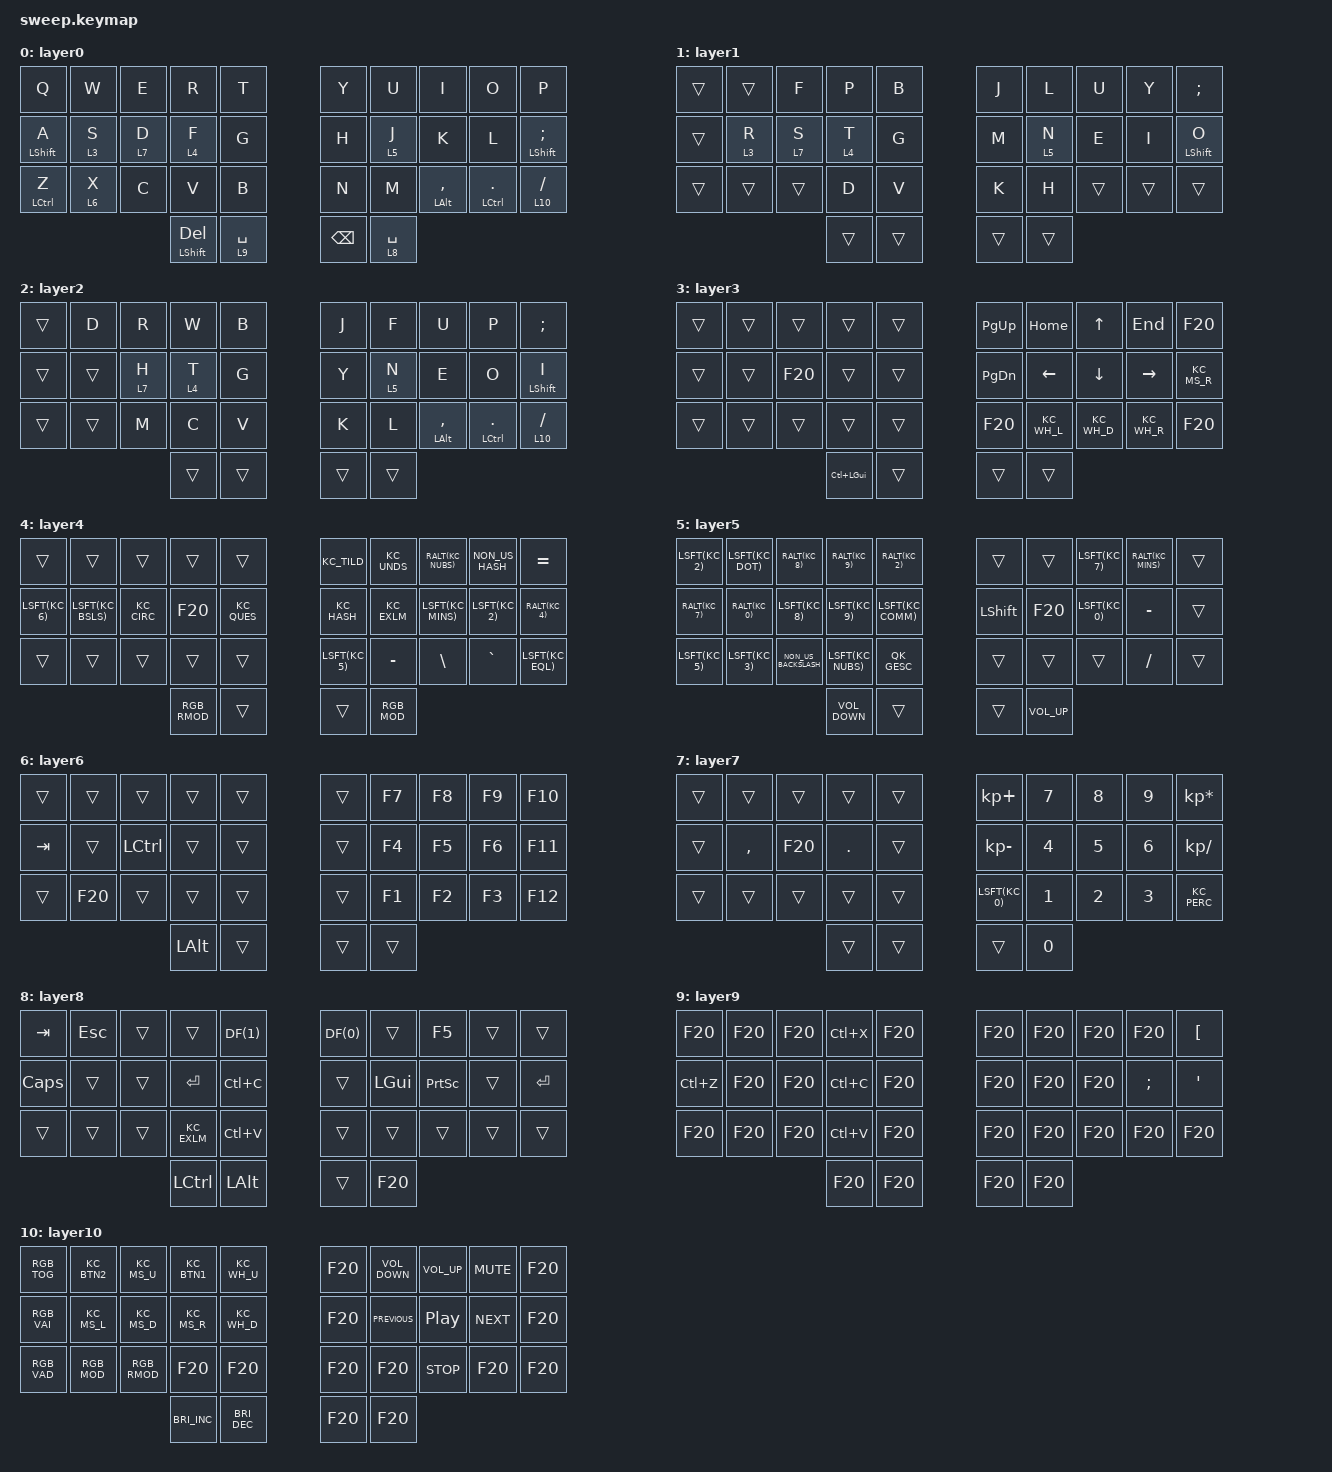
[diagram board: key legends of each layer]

  /*
  * Copyright (c) 2020 The ZMK Contributors
  *
  * SPDX-License-Identifier: MIT
  */

  #include <behaviors.dtsi>
  #include <dt-bindings/zmk/keys.h>
  #include <dt-bindings/zmk/bt.h>
  #include <dt-bindings/zmk/ext_power.h>
&mt {
   //  flavor = "tap-preferred";
   // tapping_term_ms = <200>;
};

  / {
    keymap {
      compatible = "zmk,keymap";
  layer0 {
          bindings = <
          &kp Q &kp W &kp E &kp R &kp T 							&kp Y &kp U &kp I &kp O &kp P &mt LEFT_SHIFT 
		  A &lt 3 S &lt 7 D &lt 4 F &kp G 							&kp H &lt 5 J &kp K &kp L &mt LEFT_SHIFT SEMICOLON 
		  &mt LEFT_CONTROL Z &lt 6 X &kp C &kp V &kp B 				&kp N &kp M &mt LEFT_ALT COMMA &mt LEFT_CONTROL DOT 
		  		&lt 10 SLASH &mt LEFT_SHIFT DELETE &lt 9 SPACE 		&kp BACKSPACE &lt 8 SPACE
          >;
        };layer1 {
          bindings = <
          &trans &trans &kp F &kp P &kp B &kp J 			&kp L &kp U &kp Y &kp SEMICOLON 
		  &trans &lt 3 R &lt 7 S &lt 4 T &kp G 				&kp M &lt 5 N &kp E &kp I &mt LEFT_SHIFT O 
		  &trans &trans &trans &kp D &kp V 					&kp K &kp H &trans &trans &trans 
		  						&trans &trans 				&trans &trans
          >;
        };layer2 {
          bindings = <
          &trans &kp D &kp R &kp W &kp B &kp J &kp F &kp U &kp P &kp SEMICOLON &trans &trans &lt 7 H &lt 4 T &kp G &kp Y &lt 5 N &kp E &kp O &mt LEFT_SHIFT I &trans &trans &kp M &kp C &kp V &kp K &kp L &mt LEFT_ALT COMMA &mt LEFT_CONTROL DOT &lt 10 SLASH &trans &trans &trans &trans
          >;
        };layer3 {
          bindings = <
          &trans &trans &trans &trans &trans 						&kp PAGE_UP &kp HOME &kp UP &kp END &kp F20 
		  &trans &trans &kp F20 &trans &trans 						&kp PAGE_DOWN &kp LEFT &kp DOWN &kp RIGHT KC_MS_R 
		  &trans &trans &trans &trans &trans 						&kp F20 KC_WH_L KC_WH_D KC_WH_R &kp F20 
		  					&kp LC(LEFT_GUI) &trans 				&trans &trans
          >;
        };layer4 {
          bindings = <
          &trans &trans &trans &trans &trans KC_TILD KC_UNDS RALT(KC_NUBS) &kp NON_US_HASH &kp EQUAL LSFT(KC_6) LSFT(KC_BSLS) KC_CIRC &kp F20 KC_QUES KC_HASH KC_EXLM LSFT(KC_MINS) LSFT(KC_2) RALT(KC_4) &trans &trans &trans &trans &trans LSFT(KC_5) &kp MINUS &kp BACKSLASH &kp GRAVE LSFT(KC_EQL) RGB_RMOD &trans &trans RGB_MOD
          >;
        };layer5 {
          bindings = <
          LSFT(KC_2) LSFT(KC_DOT) RALT(KC_8) RALT(KC_9) RALT(KC_2) &trans &trans LSFT(KC_7) RALT(KC_MINS) &trans RALT(KC_7) RALT(KC_0) LSFT(KC_8) LSFT(KC_9) LSFT(KC_COMM) &kp LEFT_SHIFT &kp F20 LSFT(KC_0) &kp MINUS &trans LSFT(KC_5) LSFT(KC_3) &kp NON_US_BACKSLASH LSFT(KC_NUBS) QK_GESC &trans &trans &trans &kp SLASH &trans &kp C_VOLUME_DOWN &trans &trans &kp C_VOLUME_UP
          >;
        };layer6 {
          bindings = <
          &trans &trans &trans &trans &trans &trans &kp F7 &kp F8 &kp F9 &kp F10 &kp TAB &trans &kp LEFT_CONTROL &trans &trans &trans &kp F4 &kp F5 &kp F6 &kp F11 &trans &kp F20 &trans &trans &trans &trans &kp F1 &kp F2 &kp F3 &kp F12 &kp LEFT_ALT &trans &trans &trans
          >;
        };layer7 {
          bindings = <
          &trans &trans &trans &trans &trans &kp KP_PLUS &kp N7 &kp N8 &kp N9 &kp KP_ASTERISK &trans &kp COMMA &kp F20 &kp DOT &trans &kp KP_MINUS &kp N4 &kp N5 &kp N6 &kp KP_SLASH &trans &trans &trans &trans &trans LSFT(KC_0) &kp N1 &kp N2 &kp N3 KC_PERC &trans &trans &trans &kp N0
          >;
        };layer8 {
          bindings = <
          &kp TAB &kp ESCAPE &trans &trans DF(1) DF(0) &trans &kp F5 &trans &trans &kp CAPSLOCK &trans &trans &kp ENTER &kp LC(C) &trans &kp LEFT_GUI &kp PRINTSCREEN &trans &kp ENTER &trans &trans &trans KC_EXLM &kp LC(V) &trans &trans &trans &trans &trans &kp LEFT_CONTROL &kp LEFT_ALT &trans &kp F20
          >;
        };layer9 {
          bindings = <
          &kp F20 &kp F20 &kp F20 &kp LC(X) &kp F20 &kp F20 &kp F20 &kp F20 &kp F20 &kp LEFT_BRACKET &kp LC(Z) &kp F20 &kp F20 &kp LC(C) &kp F20 &kp F20 &kp F20 &kp F20 &kp SEMICOLON &kp SINGLE_QUOTE &kp F20 &kp F20 &kp F20 &kp LC(V) &kp F20 &kp F20 &kp F20 &kp F20 &kp F20 &kp F20 &kp F20 &kp F20 &kp F20 &kp F20
          >;
        };layer10 {
          bindings = <
          RGB_TOG KC_BTN2 KC_MS_U KC_BTN1 KC_WH_U &kp F20 &kp C_VOLUME_DOWN &kp C_VOLUME_UP &kp C_MUTE &kp F20 RGB_VAI KC_MS_L KC_MS_D KC_MS_R KC_WH_D &kp F20 &kp C_PREVIOUS &kp C_PLAY_PAUSE &kp C_NEXT &kp F20 RGB_VAD RGB_MOD RGB_RMOD &kp F20 &kp F20 &kp F20 &kp F20 &kp C_STOP &kp F20 &kp F20 &kp C_BRIGHTNESS_INC &kp C_BRIGHTNESS_DEC &kp F20 &kp F20
          >;
        };
    };
  };
  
